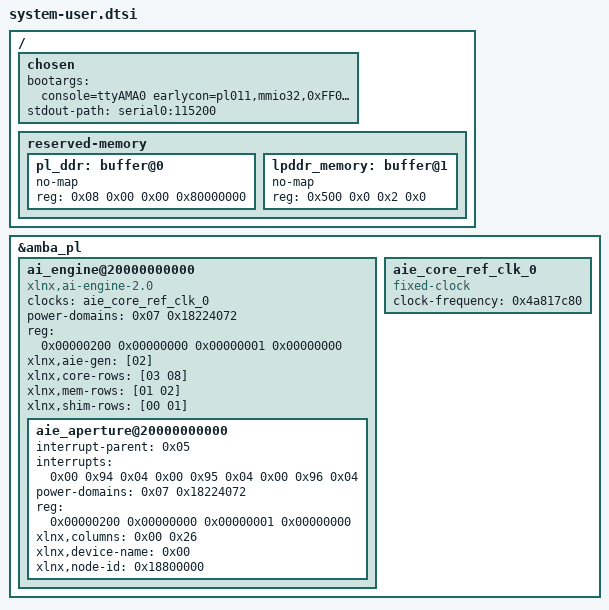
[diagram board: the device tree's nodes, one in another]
/******************************************************************************
* Copyright (C) 2020-2022 Xilinx, Inc. All rights reserved.
* Copyright (C) 2022-2023 Advanced Micro Devices, Inc. All rights reserved.
* SPDX-License-Identifier: MIT
******************************************************************************/

/*
 * /include/ "system-conf.dtsi"
 * Adding directly contents of system-conf file until CR-1139794 is fixed
 */
/ {
        chosen {
                bootargs = "console=ttyAMA0  earlycon=pl011,mmio32,0xFF000000,115200n8 clk_ignore_unused root=/dev/mmcblk0p2 rw rootwait cma=512M";
                stdout-path = "serial0:115200n8";
        };
};

/ {
	chosen {
		stdout-path = "serial0:115200";
	};

	reserved-memory {
                #address-cells = <2>;
                #size-cells = <2>;
                ranges;
                pl_ddr: buffer@0 {
                        no-map;
                        reg = <0x08 0x00 0x00 0x80000000>;
                };
                lpddr_memory: buffer@1 {
                        no-map;
                        reg = <0x500 0x0 0x2 0x0>;
                };
        };   
};

/*added as workaround for aie driver support till CR-1168276 is fixed*/
&amba_pl {
	ai_engine@20000000000 {
		#address-cells = <0x02>;
		#size-cells = <0x02>;
		clock-names = "aclk0";
		clocks = <&aie_core_ref_clk_0>;
		compatible = "xlnx,ai-engine-2.0\0xlnx,ai-engine-v2.0";
		power-domains = <0x07 0x18224072>;
		ranges;
		reg = <0x00000200 0x00000000 0x00000001 0x00000000>;
		xlnx,aie-gen = [02];
		xlnx,core-rows = [03 08];
		xlnx,mem-rows = [01 02];
		xlnx,shim-rows = [00 01];

		aie_aperture@20000000000 {
			#address-cells = <0x02>;
			#size-cells = <0x02>;
			interrupt-names = "interrupt1\0interrupt2\0interrupt3";
			interrupt-parent = <0x05>;
			interrupts = <0x00 0x94 0x04 0x00 0x95 0x04 0x00 0x96 0x04>;
			power-domains = <0x07 0x18224072>;
			reg = <0x00000200 0x00000000 0x00000001 0x00000000>;
			xlnx,columns = <0x00 0x26>;
			xlnx,device-name = <0x00>;
			xlnx,node-id = <0x18800000>;
		};
	};
	aie_core_ref_clk_0: aie_core_ref_clk_0 {
		#clock-cells = <0x00>;
		clock-frequency = <0x4a817c80>;
		compatible = "fixed-clock";
	};

};


